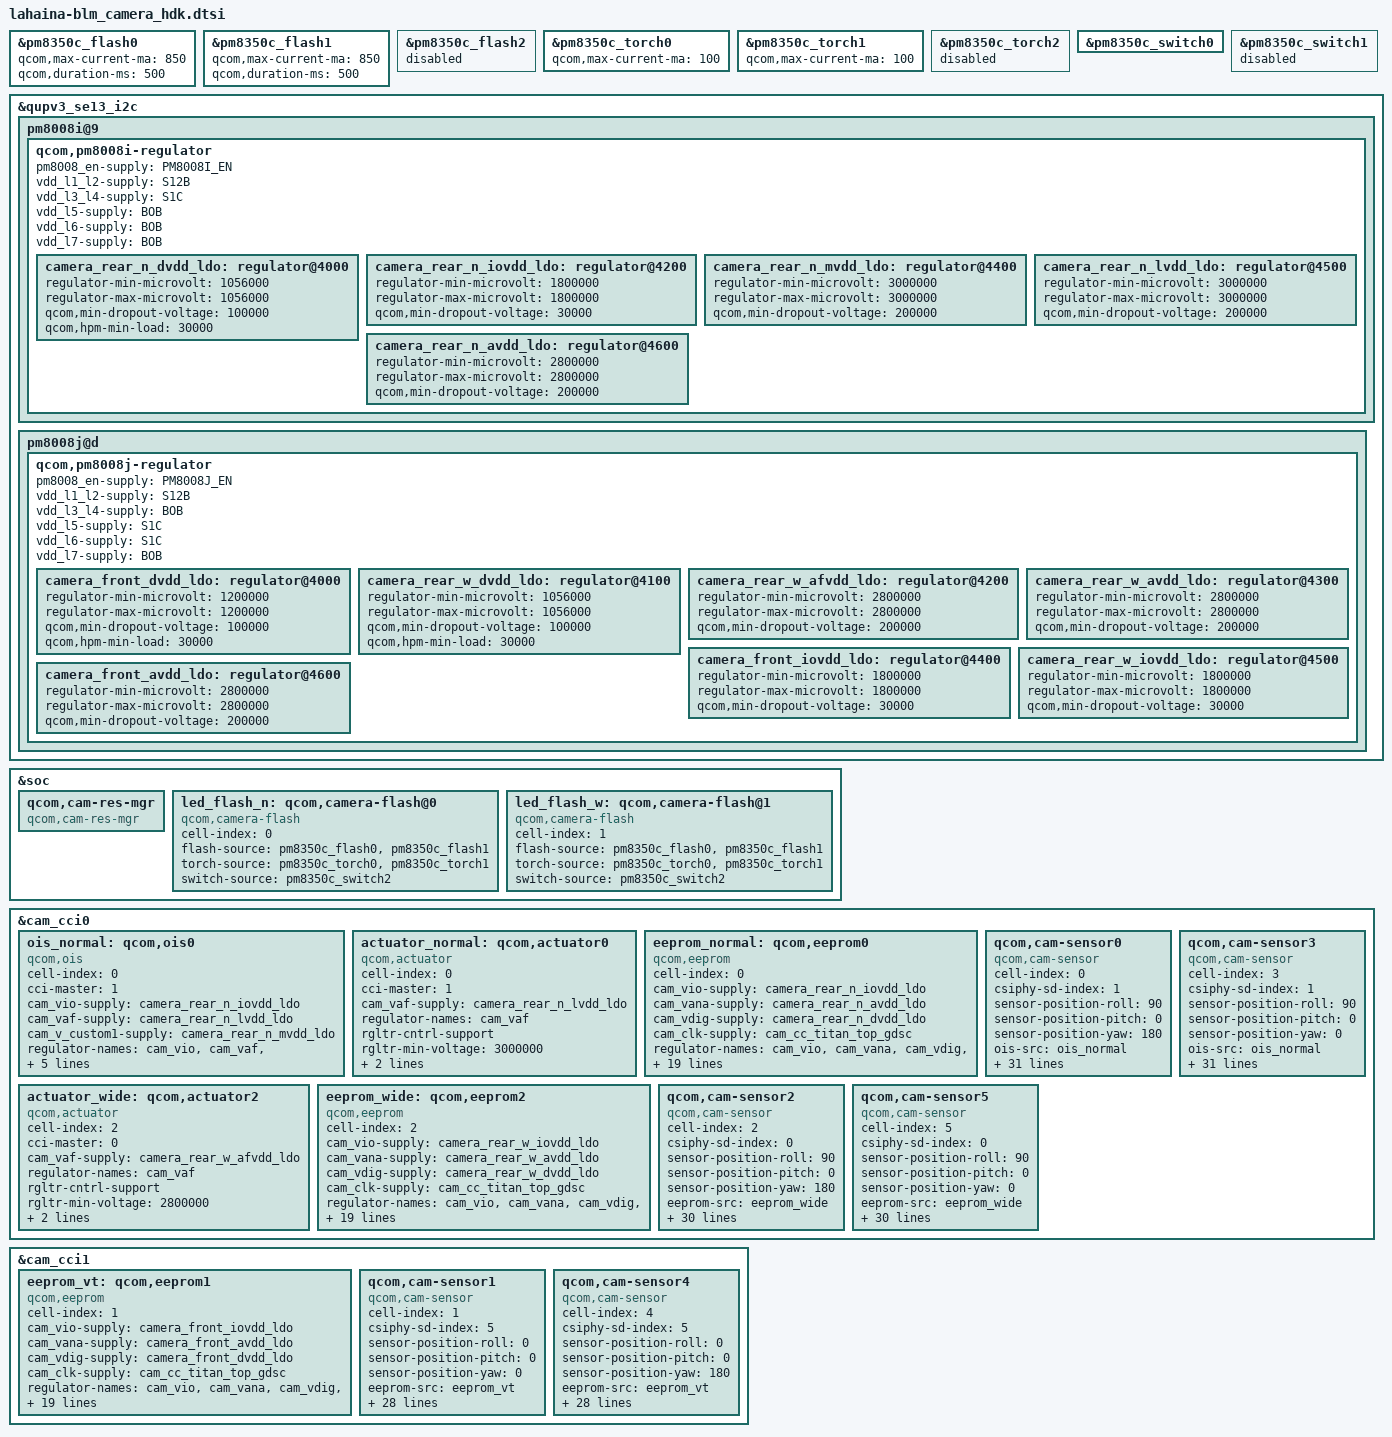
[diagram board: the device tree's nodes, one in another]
#include <dt-bindings/clock/qcom,camcc-lahaina.h>

&pm8350c_flash0 {
	status = "ok";
	qcom,max-current-ma = <850>;
	qcom,duration-ms = <500>;
};

&pm8350c_flash1 {
	status = "ok";
	qcom,max-current-ma = <850>;
	qcom,duration-ms = <500>;
};

&pm8350c_flash2 {
	status = "disabled";
};

&pm8350c_torch0 {
	status = "ok";
	qcom,max-current-ma = <100>;
};

&pm8350c_torch1 {
	status = "ok";
	qcom,max-current-ma = <100>;
};

&pm8350c_torch2 {
	status = "disabled";
};

&pm8350c_switch0 {
	status = "ok";
};

&pm8350c_switch1 {
	status = "disbled";
};

&qupv3_se13_i2c {
	pm8008i@9 {
		qcom,pm8008i-regulator {
			pm8008_en-supply = <&PM8008I_EN>;
			vdd_l1_l2-supply = <&S12B>;
			vdd_l3_l4-supply = <&S1C>;
			vdd_l5-supply = <&BOB>;
			vdd_l6-supply = <&BOB>;
			vdd_l7-supply = <&BOB>;

			camera_rear_n_dvdd_ldo: regulator@4000 {
				regulator-min-microvolt = <1056000>;
				regulator-max-microvolt = <1056000>;
				qcom,min-dropout-voltage = <100000>;
				qcom,hpm-min-load = <30000>;
			};

			camera_rear_n_iovdd_ldo: regulator@4200 {
			    regulator-min-microvolt = <1800000>;
			    regulator-max-microvolt = <1800000>;
			    qcom,min-dropout-voltage = <30000>;
			};

			camera_rear_n_mvdd_ldo: regulator@4400 {
				regulator-min-microvolt = <3000000>;
				regulator-max-microvolt = <3000000>;
				qcom,min-dropout-voltage = <200000>;
			};

			camera_rear_n_lvdd_ldo: regulator@4500 {
				regulator-min-microvolt = <3000000>;
				regulator-max-microvolt = <3000000>;
				qcom,min-dropout-voltage = <200000>;
			};

			camera_rear_n_avdd_ldo: regulator@4600 {
				regulator-min-microvolt = <2800000>;
				regulator-max-microvolt = <2800000>;
				qcom,min-dropout-voltage = <200000>;
			};
		};
	};

	pm8008j@d {
		qcom,pm8008j-regulator {
			pm8008_en-supply = <&PM8008J_EN>;
			vdd_l1_l2-supply = <&S12B>;
			vdd_l3_l4-supply = <&BOB>;
			vdd_l5-supply = <&S1C>;
			vdd_l6-supply = <&S1C>;
			vdd_l7-supply = <&BOB>;

			camera_front_dvdd_ldo: regulator@4000 {
				regulator-min-microvolt = <1200000>;
				regulator-max-microvolt = <1200000>;
				qcom,min-dropout-voltage = <100000>;
				qcom,hpm-min-load = <30000>;
			};

			camera_rear_w_dvdd_ldo: regulator@4100 {
				regulator-min-microvolt = <1056000>;
				regulator-max-microvolt = <1056000>;
				qcom,min-dropout-voltage = <100000>;
				qcom,hpm-min-load = <30000>;
			};

			camera_rear_w_afvdd_ldo: regulator@4200 {
				regulator-min-microvolt = <2800000>;
				regulator-max-microvolt = <2800000>;
				qcom,min-dropout-voltage = <200000>;
			};

			camera_rear_w_avdd_ldo: regulator@4300 {
				regulator-min-microvolt = <2800000>;
				regulator-max-microvolt = <2800000>;
				qcom,min-dropout-voltage = <200000>;
			};

			camera_front_iovdd_ldo: regulator@4400 {
			    regulator-min-microvolt = <1800000>;
			    regulator-max-microvolt = <1800000>;
			    qcom,min-dropout-voltage = <30000>;
			};

			camera_rear_w_iovdd_ldo: regulator@4500 {
			    regulator-min-microvolt = <1800000>;
			    regulator-max-microvolt = <1800000>;
			    qcom,min-dropout-voltage = <30000>;
			};

			camera_front_avdd_ldo: regulator@4600 {
				regulator-min-microvolt = <2800000>;
				regulator-max-microvolt = <2800000>;
				qcom,min-dropout-voltage = <200000>;
			};
		};
	};
};

&soc {
	qcom,cam-res-mgr {
		compatible = "qcom,cam-res-mgr";
		status = "ok";
	};

	led_flash_n: qcom,camera-flash@0 {
		cell-index = <0>;
		compatible = "qcom,camera-flash";
		flash-source = <&pm8350c_flash0 &pm8350c_flash1>;
		torch-source = <&pm8350c_torch0 &pm8350c_torch1>;
		switch-source = <&pm8350c_switch2>;
		status = "ok";
	};

	led_flash_w: qcom,camera-flash@1 {
		cell-index = <1>;
		compatible = "qcom,camera-flash";
		flash-source = <&pm8350c_flash0 &pm8350c_flash1>;
		torch-source = <&pm8350c_torch0 &pm8350c_torch1>;
		switch-source = <&pm8350c_switch2>;
		status = "ok";
	};
};

&cam_cci0 {
	ois_normal: qcom,ois0 {
		cell-index = <0>;
		compatible = "qcom,ois";
		cci-master = <1>;
		cam_vio-supply = <&camera_rear_n_iovdd_ldo>;
		cam_vaf-supply = <&camera_rear_n_lvdd_ldo>;
		cam_v_custom1-supply = <&camera_rear_n_mvdd_ldo>;
		regulator-names = "cam_vio", "cam_vaf","cam_v_custom1";
		rgltr-cntrl-support;
		rgltr-min-voltage = <1800000 3000000 3000000>;
		rgltr-max-voltage = <1800000 3000000 3000000>;
		rgltr-load-current = <150000 103000 103000>;
		status = "ok";
	};

	actuator_normal: qcom,actuator0 {
		cell-index = <0>;
		compatible = "qcom,actuator";
		cci-master = <1>;
		cam_vaf-supply = <&camera_rear_n_lvdd_ldo>;
		regulator-names = "cam_vaf";
		rgltr-cntrl-support;
		rgltr-min-voltage = <3000000>;
		rgltr-max-voltage = <3000000>;
		rgltr-load-current = <103000>;
	};

	eeprom_normal: qcom,eeprom0 {
		cell-index = <0>;
		compatible = "qcom,eeprom";
		cam_vio-supply = <&camera_rear_n_iovdd_ldo>;
		cam_vana-supply = <&camera_rear_n_avdd_ldo>;
		cam_vdig-supply = <&camera_rear_n_dvdd_ldo>;
		cam_clk-supply = <&cam_cc_titan_top_gdsc>;
		regulator-names = "cam_vio", "cam_vana", "cam_vdig", "cam_clk";
		rgltr-cntrl-support;
		rgltr-min-voltage = <1800000 2800000 1056000 0>;
		rgltr-max-voltage = <1800000 2800000 1056000 0>;
		rgltr-load-current = <150000 150000 805000 0>;
		gpio-no-mux = <0>;
		pinctrl-names = "cam_default", "cam_suspend";
		pinctrl-0 = <&cam_sensor_mclk1_active
				&cam_sensor_active_rst1>;
		pinctrl-1 = <&cam_sensor_mclk1_suspend
				&cam_sensor_suspend_rst1>;
		gpios = <&tlmm 101 0>,
			<&tlmm 16 0>;
		gpio-reset = <1>;
		gpio-req-tbl-num = <0 1>;
		gpio-req-tbl-flags = <1 0>;
		gpio-req-tbl-label = "CAMIF_MCLK1",
					"CAM_RESET1";
		cci-master = <1>;
		status = "ok";
		clocks = <&clock_camcc CAM_CC_MCLK1_CLK>;
		clock-names = "cam_clk";
		clock-cntl-level = "nominal";
		clock-rates = <19200000>;
	};

	qcom,cam-sensor0 {
		cell-index = <0>;
		compatible = "qcom,cam-sensor";
		csiphy-sd-index = <1>;
		sensor-position-roll = <90>;
		sensor-position-pitch = <0>;
		sensor-position-yaw = <180>;
		ois-src = <&ois_normal>;
		actuator-src = <&actuator_normal>;
		eeprom-src = <&eeprom_normal>;
		led-flash-src = <&led_flash_n>;
		cam_vio-supply = <&camera_rear_n_iovdd_ldo>;
		cam_vana-supply = <&camera_rear_n_avdd_ldo>;
		cam_vdig-supply = <&camera_rear_n_dvdd_ldo>;
		cam_clk-supply = <&cam_cc_titan_top_gdsc>;
		cam_bob-supply = <&pm8350c_bob>;
		regulator-names = "cam_vio", "cam_vana", "cam_vdig","cam_clk", "cam_bob";
		rgltr-cntrl-support;
		rgltr-min-voltage = <1800000 2800000 1056000 0 3300000>;
		rgltr-max-voltage = <1800000 2800000 1056000 0 3300000>;
		rgltr-load-current = <150000 150000 805000 0 150000>;
		gpio-no-mux = <0>;
		pinctrl-names = "cam_default", "cam_suspend";
		pinctrl-0 = <&cam_sensor_mclk1_active
				&cam_sensor_active_rst1>;
		pinctrl-1 = <&cam_sensor_mclk1_suspend
				&cam_sensor_suspend_rst1>;
		gpios = <&tlmm 101 0>,
			<&tlmm 16 0>;
		gpio-reset = <1>;
		gpio-req-tbl-num = <0 1>;
		gpio-req-tbl-flags = <1 0>;
		gpio-req-tbl-label = "CAMIF_MCLK1",
					"CAM_RESET1";
		cci-master = <1>;
		status = "ok";
		clocks = <&clock_camcc CAM_CC_MCLK1_CLK>;
		clock-names = "cam_clk";
		clock-cntl-level = "nominal";
		clock-rates = <19200000>;
	};

	qcom,cam-sensor3 {
		cell-index = <3>;
		compatible = "qcom,cam-sensor";
		csiphy-sd-index = <1>;
		sensor-position-roll = <90>;
		sensor-position-pitch = <0>;
		sensor-position-yaw = <0>;
		ois-src = <&ois_normal>;
		actuator-src = <&actuator_normal>;
		eeprom-src = <&eeprom_normal>;
		led-flash-src = <&led_flash_n>;
		cam_vio-supply = <&camera_rear_n_iovdd_ldo>;
		cam_vana-supply = <&camera_rear_n_avdd_ldo>;
		cam_vdig-supply = <&camera_rear_n_dvdd_ldo>;
		cam_clk-supply = <&cam_cc_titan_top_gdsc>;
		cam_bob-supply = <&pm8350c_bob>;
		regulator-names = "cam_vio", "cam_vana", "cam_vdig","cam_clk", "cam_bob";
		rgltr-cntrl-support;
		rgltr-min-voltage = <1800000 2800000 1056000 0 3300000>;
		rgltr-max-voltage = <1800000 2800000 1056000 0 3300000>;
		rgltr-load-current = <150000 150000 805000 0 150000>;
		gpio-no-mux = <0>;
		pinctrl-names = "cam_default", "cam_suspend";
		pinctrl-0 = <&cam_sensor_mclk1_active
				&cam_sensor_active_rst1>;
		pinctrl-1 = <&cam_sensor_mclk1_suspend
				&cam_sensor_suspend_rst1>;
		gpios = <&tlmm 101 0>,
			<&tlmm 16 0>;
		gpio-reset = <1>;
		gpio-req-tbl-num = <0 1>;
		gpio-req-tbl-flags = <1 0>;
		gpio-req-tbl-label = "CAMIF_MCLK1",
					"CAM_RESET1";
		cci-master = <1>;
		status = "ok";
		clocks = <&clock_camcc CAM_CC_MCLK1_CLK>;
		clock-names = "cam_clk";
		clock-cntl-level = "nominal";
		clock-rates = <19200000>;
	};
	actuator_wide: qcom,actuator2 {
		cell-index = <2>;
		compatible = "qcom,actuator";
		cci-master = <0>;
		cam_vaf-supply = <&camera_rear_w_afvdd_ldo>;
		regulator-names = "cam_vaf";
		rgltr-cntrl-support;
		rgltr-min-voltage = <2800000>;
		rgltr-max-voltage = <2800000>;
		rgltr-load-current = <103000>;
	};

	eeprom_wide: qcom,eeprom2 {
		cell-index = <2>;
		compatible = "qcom,eeprom";
		cam_vio-supply = <&camera_rear_w_iovdd_ldo>;
		cam_vana-supply = <&camera_rear_w_avdd_ldo>;
		cam_vdig-supply = <&camera_rear_w_dvdd_ldo>;
		cam_clk-supply = <&cam_cc_titan_top_gdsc>;
		regulator-names = "cam_vio", "cam_vana", "cam_vdig", "cam_clk";
		rgltr-cntrl-support;
		rgltr-min-voltage = <1800000 2800000 1056000 0>;
		rgltr-max-voltage = <1800000 2800000 1056000 0>;
		rgltr-load-current = <10000 52000 805000 0>;
		gpio-no-mux = <0>;
		pinctrl-names = "cam_default", "cam_suspend";
		pinctrl-0 = <&cam_sensor_mclk0_active
				 &cam_sensor_active_rst0>;
		pinctrl-1 = <&cam_sensor_mclk0_suspend
				 &cam_sensor_suspend_rst0>;
		gpios = <&tlmm 100 0>,
			<&tlmm 17 0>;
		gpio-reset = <1>;
		gpio-req-tbl-num = <0 1>;
		gpio-req-tbl-flags = <1 0>;
		gpio-req-tbl-label = "CAMIF_MCLK0",
					"CAM_RESET0";
		cci-master = <0>;
		status = "ok";
		clocks = <&clock_camcc CAM_CC_MCLK0_CLK>;
		clock-names = "cam_clk";
		clock-cntl-level = "nominal";
		clock-rates = <19200000>;
	};

	qcom,cam-sensor2 {
		cell-index = <2>;
		compatible = "qcom,cam-sensor";
		csiphy-sd-index = <0>;
		sensor-position-roll = <90>;
		sensor-position-pitch = <0>;
		sensor-position-yaw = <180>;
		eeprom-src = <&eeprom_wide>;
		actuator-src = <&actuator_wide>;
		led-flash-src = <&led_flash_w>;
		cam_vio-supply = <&camera_rear_w_iovdd_ldo>;
		cam_vana-supply = <&camera_rear_w_avdd_ldo>;
		cam_vdig-supply = <&camera_rear_w_dvdd_ldo>;
		cam_clk-supply = <&cam_cc_titan_top_gdsc>;
		cam_bob-supply = <&pm8350c_bob>;
		regulator-names = "cam_vio", "cam_vana", "cam_vdig",
			"cam_clk", "cam_bob";
		rgltr-cntrl-support;
		rgltr-min-voltage = <1800000 2800000 1056000 0 3300000>;
		rgltr-max-voltage = <1800000 2800000 1056000 0 3300000>;
		rgltr-load-current = <10000 52000 805000 0 2000000>;
		gpio-no-mux = <0>;
		pinctrl-names = "cam_default", "cam_suspend";
		pinctrl-0 = <&cam_sensor_mclk0_active
				&cam_sensor_active_rst0>;
		pinctrl-1 = <&cam_sensor_mclk0_suspend
				&cam_sensor_suspend_rst0>;
		gpios = <&tlmm 100 0>,
			<&tlmm 17 0>;
		gpio-reset = <1>;
		gpio-req-tbl-num = <0 1>;
		gpio-req-tbl-flags = <1 0>;
		gpio-req-tbl-label = "CAMIF_MCLK0",
					"CAM_RESET0";
		cci-master = <0>;
		status = "ok";
		clocks = <&clock_camcc CAM_CC_MCLK0_CLK>;
		clock-names = "cam_clk";
		clock-cntl-level = "nominal";
		clock-rates = <19200000>;
	};

	qcom,cam-sensor5 {
		cell-index = <5>;
		compatible = "qcom,cam-sensor";
		csiphy-sd-index = <0>;
		sensor-position-roll = <90>;
		sensor-position-pitch = <0>;
		sensor-position-yaw = <0>;
		eeprom-src = <&eeprom_wide>;
		actuator-src = <&actuator_wide>;
		led-flash-src = <&led_flash_w>;
		cam_vio-supply = <&camera_rear_w_iovdd_ldo>;
		cam_vana-supply = <&camera_rear_w_avdd_ldo>;
		cam_vdig-supply = <&camera_rear_w_dvdd_ldo>;
		cam_clk-supply = <&cam_cc_titan_top_gdsc>;
		cam_bob-supply = <&pm8350c_bob>;
		regulator-names = "cam_vio", "cam_vana", "cam_vdig",
			"cam_clk", "cam_bob";
		rgltr-cntrl-support;
		rgltr-min-voltage = <1800000 2800000 1056000 0 3300000>;
		rgltr-max-voltage = <1800000 2800000 1056000 0 3300000>;
		rgltr-load-current = <10000 52000 805000 0 2000000>;
		gpio-no-mux = <0>;
		pinctrl-names = "cam_default", "cam_suspend";
		pinctrl-0 = <&cam_sensor_mclk0_active
				&cam_sensor_active_rst0>;
		pinctrl-1 = <&cam_sensor_mclk0_suspend
				&cam_sensor_suspend_rst0>;
		gpios = <&tlmm 100 0>,
			<&tlmm 17 0>;
		gpio-reset = <1>;
		gpio-req-tbl-num = <0 1>;
		gpio-req-tbl-flags = <1 0>;
		gpio-req-tbl-label = "CAMIF_MCLK0",
					"CAM_RESET0";
		cci-master = <0>;
		status = "ok";
		clocks = <&clock_camcc CAM_CC_MCLK0_CLK>;
		clock-names = "cam_clk";
		clock-cntl-level = "nominal";
		clock-rates = <19200000>;
	};
};

&cam_cci1 {
	eeprom_vt: qcom,eeprom1 {
		cell-index = <1>;
		compatible = "qcom,eeprom";
		cam_vio-supply = <&camera_front_iovdd_ldo>;
		cam_vana-supply = <&camera_front_avdd_ldo>;
		cam_vdig-supply = <&camera_front_dvdd_ldo>;
		cam_clk-supply = <&cam_cc_titan_top_gdsc>;
		regulator-names = "cam_vio", "cam_vana", "cam_vdig", "cam_clk";
		rgltr-cntrl-support;
		rgltr-min-voltage = <1800000 2800000 1200000 0>;
		rgltr-max-voltage = <1800000 2800000 1200000 0>;
		rgltr-load-current = <5000 35000 301000 0>;
		gpio-no-mux = <0>;
		pinctrl-names = "cam_default", "cam_suspend";
		pinctrl-0 = <&cam_sensor_mclk5_active
				 &cam_sensor_active_rst5>;
		pinctrl-1 = <&cam_sensor_mclk5_suspend
				 &cam_sensor_suspend_rst5>;
		gpios = <&tlmm 105 0>,
			<&tlmm 115 0>;
		gpio-reset = <1>;
		gpio-req-tbl-num = <0 1>;
		gpio-req-tbl-flags = <1 0>;
		gpio-req-tbl-label = "CAMIF_MCLK5",
					"CAM_RESET5";
		cci-master = <0>;
		status = "ok";
		clocks = <&clock_camcc CAM_CC_MCLK5_CLK>;
		clock-names = "cam_clk";
		clock-cntl-level = "nominal";
		clock-rates = <19200000>;
	};

	qcom,cam-sensor1 {
		cell-index = <1>;
		compatible = "qcom,cam-sensor";
		csiphy-sd-index = <5>;
		sensor-position-roll = <0>;
		sensor-position-pitch = <0>;
		sensor-position-yaw = <0>;
		eeprom-src = <&eeprom_vt>;
		cam_vio-supply = <&camera_front_iovdd_ldo>;
		cam_vana-supply = <&camera_front_avdd_ldo>;
		cam_vdig-supply = <&camera_front_dvdd_ldo>;
		cam_clk-supply = <&cam_cc_titan_top_gdsc>;
		cam_bob-supply = <&pm8350c_bob>;
		regulator-names = "cam_vio", "cam_vana", "cam_vdig",
			"cam_clk", "cam_bob";
		rgltr-cntrl-support;
		rgltr-min-voltage = <1800000 2800000 1200000 0 3300000>;
		rgltr-max-voltage = <1800000 2800000 1200000 0 3300000>;
		rgltr-load-current = <5000 35000 301000 0 2000000>;
		gpio-no-mux = <0>;
		pinctrl-names = "cam_default", "cam_suspend";
		pinctrl-0 = <&cam_sensor_mclk5_active
				 &cam_sensor_active_rst5>;
		pinctrl-1 = <&cam_sensor_mclk5_suspend
				 &cam_sensor_suspend_rst5>;
		gpios = <&tlmm 105 0>,
			<&tlmm 115 0>;
		gpio-reset = <1>;
		gpio-req-tbl-num = <0 1>;
		gpio-req-tbl-flags = <1 0>;
		gpio-req-tbl-label = "CAMIF_MCLK5",
					"CAM_RESET5";
		cci-master = <0>;
		status = "ok";
		clocks = <&clock_camcc CAM_CC_MCLK5_CLK>;
		clock-names = "cam_clk";
		clock-cntl-level = "nominal";
		clock-rates = <19200000>;
	};

	qcom,cam-sensor4 {
		cell-index = <4>;
		compatible = "qcom,cam-sensor";
		csiphy-sd-index = <5>;
		sensor-position-roll = <0>;
		sensor-position-pitch = <0>;
		sensor-position-yaw = <180>;
		eeprom-src = <&eeprom_vt>;
		cam_vio-supply = <&camera_front_iovdd_ldo>;
		cam_vana-supply = <&camera_front_avdd_ldo>;
		cam_vdig-supply = <&camera_front_dvdd_ldo>;
		cam_clk-supply = <&cam_cc_titan_top_gdsc>;
		cam_bob-supply = <&pm8350c_bob>;
		regulator-names = "cam_vio", "cam_vana", "cam_vdig",
			"cam_clk", "cam_bob";
		rgltr-cntrl-support;
		rgltr-min-voltage = <1800000 2800000 1200000 0 3300000>;
		rgltr-max-voltage = <1800000 2800000 1200000 0 3300000>;
		rgltr-load-current = <5000 35000 301000 0 2000000>;
		gpio-no-mux = <0>;
		pinctrl-names = "cam_default", "cam_suspend";
		pinctrl-0 = <&cam_sensor_mclk5_active
				 &cam_sensor_active_rst5>;
		pinctrl-1 = <&cam_sensor_mclk5_suspend
				 &cam_sensor_suspend_rst5>;
		gpios = <&tlmm 105 0>,
			<&tlmm 115 0>;
		gpio-reset = <1>;
		gpio-req-tbl-num = <0 1>;
		gpio-req-tbl-flags = <1 0>;
		gpio-req-tbl-label = "CAMIF_MCLK5",
					"CAM_RESET5";
		cci-master = <0>;
		status = "ok";
		clocks = <&clock_camcc CAM_CC_MCLK5_CLK>;
		clock-names = "cam_clk";
		clock-cntl-level = "nominal";
		clock-rates = <19200000>;
	};
};
